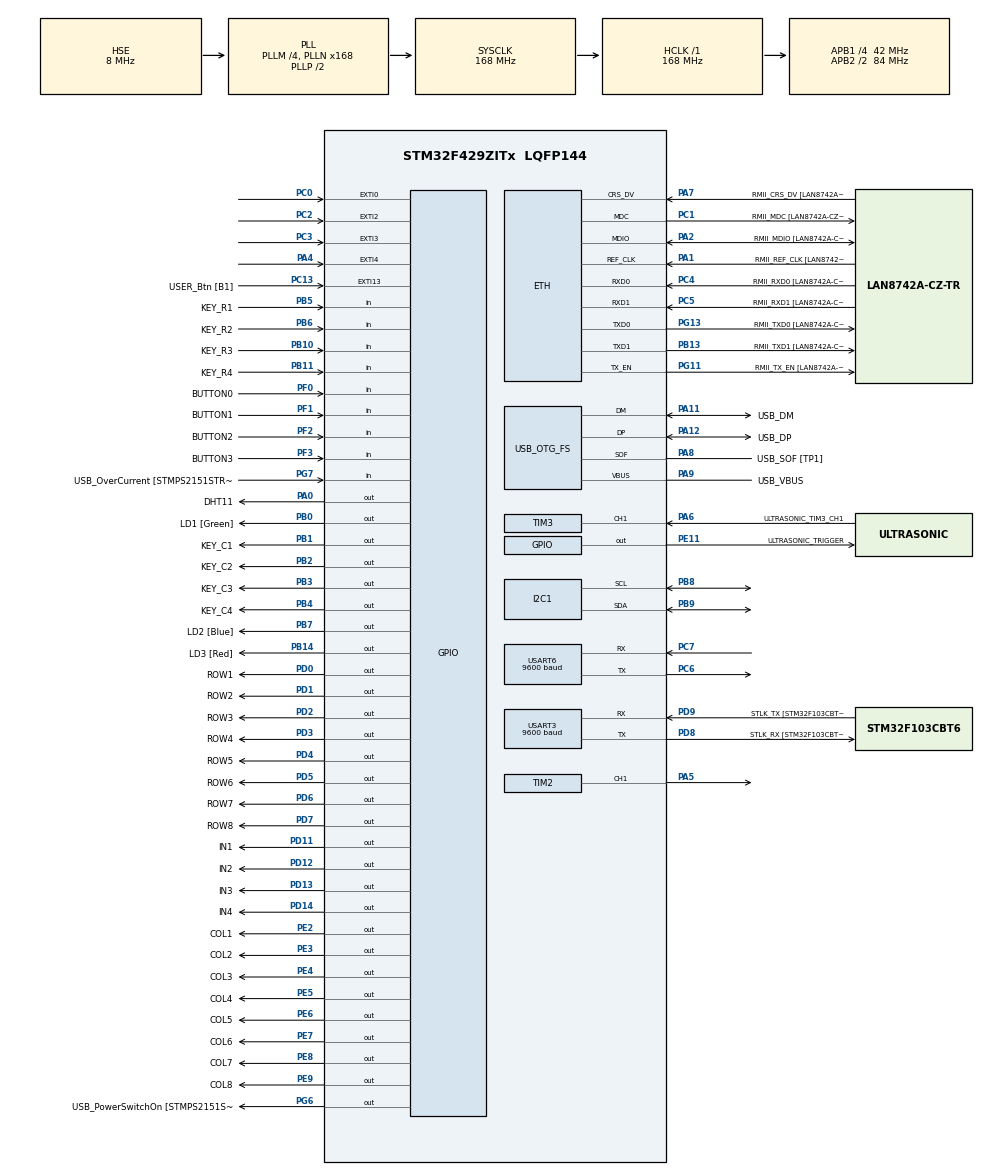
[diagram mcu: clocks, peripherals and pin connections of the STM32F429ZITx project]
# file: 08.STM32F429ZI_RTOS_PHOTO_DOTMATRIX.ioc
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ETH.MediaInterface=HAL_ETH_RMII_MODE
ETH.PHY_Name=LAN8742A_PHY_ADDRESS
ETH.PHY_Value=0
ETH.PhyAddress=0
FREERTOS.Mutexes01=myMutex01,Dynamic,NULL
FREERTOS.Tasks01=defaultTask,24,128,StartDefaultTask,Default,NULL,Dynamic,NULL,NULL;myTask02,8,128,StartTask02,Default,NULL,Dynamic,NULL,NULL;myTask03,8,128,StartTask03,Default,NULL,Dynamic,NULL,NULL;myTask04,8,128,StartTask04,Default,NULL,Dynamic,NULL,NULL
FREERTOS.configUSE_NEWLIB_REENTRANT=1
Mcu.Family=STM32F4
Mcu.Name=STM32F429ZITx
Mcu.Package=LQFP144
NVIC.EXTI0_IRQn=true\:5\:0\:false\:false\:true\:true\:true\:true\:true
NVIC.EXTI2_IRQn=true\:5\:0\:false\:false\:true\:true\:true\:true\:true
NVIC.EXTI3_IRQn=true\:5\:0\:false\:false\:true\:true\:true\:true\:true
NVIC.EXTI4_IRQn=true\:5\:0\:false\:false\:true\:true\:true\:true\:true
NVIC.I2C1_ER_IRQn=true\:5\:0\:false\:false\:true\:true\:true\:true\:true
NVIC.I2C1_EV_IRQn=true\:5\:0\:false\:false\:true\:true\:true\:true\:true
NVIC.PriorityGroup=NVIC_PRIORITYGROUP_4
NVIC.TIM1_TRG_COM_TIM11_IRQn=true\:5\:0\:false\:false\:true\:true\:true\:true\:true
NVIC.TIM1_UP_TIM10_IRQn=true\:15\:0\:false\:false\:true\:false\:true\:true\:true
NVIC.TIM2_IRQn=true\:5\:0\:false\:false\:true\:true\:true\:true\:true
NVIC.TIM3_IRQn=true\:5\:0\:false\:false\:true\:true\:true\:true\:true
NVIC.TimeBase=TIM1_UP_TIM10_IRQn
NVIC.TimeBaseIP=TIM1
NVIC.USART3_IRQn=true\:5\:0\:false\:false\:true\:true\:true\:true\:true
NVIC.USART6_IRQn=true\:5\:0\:false\:false\:true\:true\:true\:true\:true
PA0/WKUP.GPIO_Label=DHT11
PA0/WKUP.Signal=GPIO_Output
PA1.GPIO_Label=RMII_REF_CLK [LAN8742A-CZ-TR_REFCLK0]
PA1.Mode=RMII
PA1.Signal=ETH_REF_CLK
PA10.GPIO_Label=USB_ID
PA10.Signal=USB_OTG_FS_ID
PA11.GPIO_Label=USB_DM
PA11.Mode=Device_Only
PA11.Signal=USB_OTG_FS_DM
PA12.GPIO_Label=USB_DP
PA12.Mode=Device_Only
PA12.Signal=USB_OTG_FS_DP
PA13.GPIO_Label=TMS
PA13.Mode=Serial_Wire
PA13.Signal=SYS_JTMS-SWDIO
PA14.GPIO_Label=TCK
PA14.Mode=Serial_Wire
PA14.Signal=SYS_JTCK-SWCLK
PA2.GPIO_Label=RMII_MDIO [LAN8742A-CZ-TR_MDIO]
PA2.Mode=RMII
PA2.Signal=ETH_MDIO
PA4.GPIO_ModeDefaultEXTI=GPIO_MODE_IT_RISING
PA4.Signal=GPXTI4
PA5.Signal=S_TIM2_CH1_ETR
PA6.GPIO_Label=ULTRASONIC_TIM3_CH1
PA6.Signal=S_TIM3_CH1
PA7.GPIO_Label=RMII_CRS_DV [LAN8742A-CZ-TR_CRS_DV]
PA7.Mode=RMII
PA7.Signal=ETH_CRS_DV
PA8.GPIO_Label=USB_SOF [TP1]
PA8.Mode=Activate_SOF_FS
PA8.Signal=USB_OTG_FS_SOF
PA9.GPIO_Label=USB_VBUS
PA9.Mode=Activate_VBUS
PA9.Signal=USB_OTG_FS_VBUS
PB0.GPIO_Label=LD1 [Green]
PB0.Signal=GPIO_Output
PB1.GPIO_Label=KEY_C1
PB1.Signal=GPIO_Output
PB10.GPIO_Label=KEY_R3
PB10.GPIO_PuPd=GPIO_PULLUP
PB10.Signal=GPIO_Input
PB11.GPIO_Label=KEY_R4
PB11.GPIO_PuPd=GPIO_PULLUP
PB11.Signal=GPIO_Input
PB13.GPIO_Label=RMII_TXD1 [LAN8742A-CZ-TR_TXD1]
PB13.Mode=RMII
PB13.Signal=ETH_TXD1
PB14.GPIO_Label=LD3 [Red]
PB14.Signal=GPIO_Output
PB2/BOOT1.GPIO_Label=KEY_C2
PB2/BOOT1.Signal=GPIO_Output
PB3.GPIO_Label=KEY_C3
PB3.Signal=GPIO_Output
PB4.GPIO_Label=KEY_C4
PB4.Signal=GPIO_Output
PB5.GPIO_Label=KEY_R1
PB5.GPIO_PuPd=GPIO_PULLUP
PB5.Signal=GPIO_Input
PB6.GPIO_Label=KEY_R2
PB6.GPIO_PuPd=GPIO_PULLUP
PB6.Signal=GPIO_Input
PB7.GPIO_Label=LD2 [Blue]
PB7.Signal=GPIO_Output
PB8.Mode=I2C
PB8.Signal=I2C1_SCL
PB9.Mode=I2C
PB9.Signal=I2C1_SDA
PC0.Signal=GPXTI0
PC1.GPIO_Label=RMII_MDC [LAN8742A-CZ-TR_MDC]
PC1.Mode=RMII
PC1.Signal=ETH_MDC
PC13.GPIO_Label=USER_Btn [B1]
PC13.Signal=GPXTI13
PC14/OSC32_IN.Mode=LSE-External-Oscillator
PC14/OSC32_IN.Signal=RCC_OSC32_IN
PC15/OSC32_OUT.Mode=LSE-External-Oscillator
PC15/OSC32_OUT.Signal=RCC_OSC32_OUT
PC2.Signal=GPXTI2
PC3.Signal=GPXTI3
PC4.GPIO_Label=RMII_RXD0 [LAN8742A-CZ-TR_RXD0]
PC4.Mode=RMII
PC4.Signal=ETH_RXD0
PC5.GPIO_Label=RMII_RXD1 [LAN8742A-CZ-TR_RXD1]
PC5.Mode=RMII
PC5.Signal=ETH_RXD1
PC6.Mode=Asynchronous
PC6.Signal=USART6_TX
PC7.Mode=Asynchronous
PC7.Signal=USART6_RX
PD0.GPIO_Label=ROW1
PD0.Signal=GPIO_Output
PD1.GPIO_Label=ROW2
PD1.Signal=GPIO_Output
PD11.GPIO_Label=IN1
PD11.Signal=GPIO_Output
PD12.GPIO_Label=IN2
PD12.Signal=GPIO_Output
PD13.GPIO_Label=IN3
PD13.Signal=GPIO_Output
PD14.GPIO_Label=IN4
PD14.Signal=GPIO_Output
PD2.GPIO_Label=ROW3
PD2.Signal=GPIO_Output
PD3.GPIO_Label=ROW4
PD3.Signal=GPIO_Output
PD4.GPIO_Label=ROW5
PD4.Signal=GPIO_Output
PD5.GPIO_Label=ROW6
PD5.Signal=GPIO_Output
PD6.GPIO_Label=ROW7
PD6.Signal=GPIO_Output
PD7.GPIO_Label=ROW8
PD7.Signal=GPIO_Output
PD8.GPIO_Label=STLK_RX [STM32F103CBT6_PA3]
PD8.Mode=Asynchronous
PD8.Signal=USART3_TX
PD9.GPIO_Label=STLK_TX [STM32F103CBT6_PA2]
PD9.Mode=Asynchronous
PD9.Signal=USART3_RX
PE11.GPIO_Label=ULTRASONIC_TRIGGER
PE11.Signal=GPIO_Output
PE2.GPIO_Label=COL1
PE2.Signal=GPIO_Output
PE3.GPIO_Label=COL2
PE3.Signal=GPIO_Output
PE4.GPIO_Label=COL3
PE4.Signal=GPIO_Output
PE5.GPIO_Label=COL4
PE5.Signal=GPIO_Output
PE6.GPIO_Label=COL5
PE6.Signal=GPIO_Output
PE7.GPIO_Label=COL6
PE7.Signal=GPIO_Output
PE8.GPIO_Label=COL7
PE8.Signal=GPIO_Output
PE9.GPIO_Label=COL8
PE9.Signal=GPIO_Output
PF0.GPIO_Label=BUTTON0
PF0.Signal=GPIO_Input
PF1.GPIO_Label=BUTTON1
PF1.Signal=GPIO_Input
PF2.GPIO_Label=BUTTON2
PF2.Signal=GPIO_Input
PF3.GPIO_Label=BUTTON3
PF3.Signal=GPIO_Input
PG11.GPIO_Label=RMII_TX_EN [LAN8742A-CZ-TR_TXEN]
PG11.Mode=RMII
PG11.Signal=ETH_TX_EN
PG13.GPIO_Label=RMII_TXD0 [LAN8742A-CZ-TR_TXD0]
PG13.Mode=RMII
PG13.Signal=ETH_TXD0
PG6.GPIO_Label=USB_PowerSwitchOn [STMPS2151STR_EN]
PG6.Signal=GPIO_Output
PG7.GPIO_Label=USB_OverCurrent [STMPS2151STR_FAULT]
PG7.Signal=GPIO_Input
PH0/OSC_IN.GPIO_Label=MCO [STM32F103CBT6_PA8]
PH0/OSC_IN.Mode=HSE-External-Clock-Source
PH0/OSC_IN.Signal=RCC_OSC_IN
PH1/OSC_OUT.Mode=HSE-External-Clock-Source
PH1/OSC_OUT.Signal=RCC_OSC_OUT
ProjectManager.HeapSize=0x200
ProjectManager.StackSize=0x400
ProjectManager.TargetToolchain=STM32CubeIDE
RCC.48MHZClocksFreq_Value=48000000
RCC.AHBFreq_Value=168000000
RCC.APB1CLKDivider=RCC_HCLK_DIV4
RCC.APB1Freq_Value=42000000
RCC.APB1TimFreq_Value=84000000
RCC.APB2CLKDivider=RCC_HCLK_DIV2
RCC.APB2Freq_Value=84000000
RCC.APB2TimFreq_Value=168000000
RCC.CortexFreq_Value=168000000
RCC.HCLKFreq_Value=168000000
RCC.HSE_VALUE=8000000
RCC.HSI_VALUE=16000000
RCC.PLLM=4
RCC.PLLMUL=RCC_PLL_MUL9
RCC.PLLN=168
RCC.PLLQ=7
RCC.PRESCALERUSB=RCC_USBCLKSOURCE_PLL_DIV1_5
RCC.SYSCLKFreq_VALUE=168000000
RCC.SYSCLKSource=RCC_SYSCLKSOURCE_PLLCLK
RCC.SYSCLKSourceVirtual=RCC_SYSCLKSOURCE_PLLCLK
RCC.USBFreq_Value=48000000
RCC.VCOOutputFreq_Value=336000000
RTC.Date=5
RTC.Hours=13
RTC.Minutes=37
RTC.Month=RTC_MONTH_JULY
RTC.WeekDay=RTC_WEEKDAY_WEDNESDAY
RTC.Year=23
SH.S_TIM2_CH1_ETR.0=TIM2_CH1,PWM Generation1 CH1
SH.S_TIM3_CH1.0=TIM3_CH1,Input_Capture1_from_TI1
TIM10.Period=10000-1
TIM10.Prescaler=168-1
TIM11.Prescaler=168-1
TIM2.Channel-PWM\ Generation1\ CH1=TIM_CHANNEL_1
TIM2.Period=1000-1
TIM2.Prescaler=3360-1
TIM2.Pulse-PWM\ Generation1\ CH1=500-1
TIM3.Channel-Input_Capture1_from_TI1=TIM_CHANNEL_1
TIM3.ICPolarity_CH1=TIM_INPUTCHANNELPOLARITY_BOTHEDGE
TIM3.Prescaler=168-1
USART3.BaudRate=9600
USART3.VirtualMode=VM_ASYNC
USART6.BaudRate=9600
USART6.VirtualMode=VM_ASYNC
USB_OTG_FS.VirtualMode=Device_Only
VP_FREERTOS_VS_CMSIS_V2.Mode=CMSIS_V2
VP_RTC_VS_RTC_Activate.Mode=RTC_Enabled
VP_RTC_VS_RTC_Calendar.Mode=RTC_Calendar
VP_SYS_VS_tim1.Mode=TIM1
VP_TIM10_VS_ClockSourceINT.Mode=Enable_Timer
VP_TIM11_VS_ClockSourceINT.Mode=Enable_Timer
VP_TIM3_VS_ClockSourceINT.Mode=Internal
board=NUCLEO-F429ZI

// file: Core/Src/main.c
/* USER CODE BEGIN Header */
/**
  ******************************************************************************
  * @file           : main.c
  * @brief          : Main program body
  ******************************************************************************
  * @attention
  *
  * Copyright (c) 2023 STMicroelectronics.
  * All rights reserved.
  *
  * This software is licensed under terms that can be found in the LICENSE file
  * in the root directory of this software component.
  * If no LICENSE file comes with this software, it is provided AS-IS.
  *
  ******************************************************************************
  */
/* USER CODE END Header */
#include "main.h"
#include "string.h"
#include "cmsis_os.h"

ETH_TxPacketConfig TxConfig;
ETH_DMADescTypeDef  DMARxDscrTab[ETH_RX_DESC_CNT]; /* Ethernet Rx DMA Descriptors */
ETH_DMADescTypeDef  DMATxDscrTab[ETH_TX_DESC_CNT]; /* Ethernet Tx DMA Descriptors */

ETH_HandleTypeDef heth;

I2C_HandleTypeDef hi2c1;

RTC_HandleTypeDef hrtc;

TIM_HandleTypeDef htim2;
TIM_HandleTypeDef htim3;
TIM_HandleTypeDef htim10;
TIM_HandleTypeDef htim11;

UART_HandleTypeDef huart3;
UART_HandleTypeDef huart6;

PCD_HandleTypeDef hpcd_USB_OTG_FS;

/* Definitions for defaultTask */
osThreadId_t defaultTaskHandle;
const osThreadAttr_t defaultTask_attributes = {
  .name = "defaultTask",
  .stack_size = 128 * 4,
  .priority = (osPriority_t) osPriorityNormal,
};
/* Definitions for myTask02 */
osThreadId_t myTask02Handle;
const osThreadAttr_t myTask02_attributes = {
  .name = "myTask02",
  .stack_size = 128 * 4,
  .priority = (osPriority_t) osPriorityLow,
};
/* Definitions for myTask03 */
osThreadId_t myTask03Handle;
const osThreadAttr_t myTask03_attributes = {
  .name = "myTask03",
  .stack_size = 128 * 4,
  .priority = (osPriority_t) osPriorityLow,
};
/* Definitions for myTask04 */
osThreadId_t myTask04Handle;
const osThreadAttr_t myTask04_attributes = {
  .name = "myTask04",
  .stack_size = 128 * 4,
  .priority = (osPriority_t) osPriorityLow,
};
/* Definitions for myMutex01 */
osMutexId_t myMutex01Handle;
const osMutexAttr_t myMutex01_attributes = {
  .name = "myMutex01"
};
/* USER CODE BEGIN PV */
uint8_t rx_data; // PC data #define uint8_t unsigned char
uint8_t bt_data; // BT data
/* USER CODE END PV */

void SystemClock_Config(void);
static void MX_GPIO_Init(void);
static void MX_ETH_Init(void);
static void MX_USART3_UART_Init(void);
static void MX_USB_OTG_FS_PCD_Init(void);
static void MX_TIM10_Init(void);
static void MX_TIM11_Init(void);
static void MX_RTC_Init(void);
static void MX_I2C1_Init(void);
static void MX_USART6_UART_Init(void);
static void MX_TIM2_Init(void);
static void MX_TIM3_Init(void);
void StartDefaultTask(void *argument);
void StartTask02(void *argument);
void StartTask03(void *argument);
void StartTask04(void *argument);

/* USER CODE BEGIN PFP */
extern void pc_command_processing(void);
extern void bt_command_processing(void);
extern void get_rtc_time(void);
extern void i2c_lcd_main(void);
extern void i2c_lcd_init(void);
extern void DHT11_main(void);
extern void DHT11_Init(void);
extern void DHT11_processing(void);
extern void button0_status_check(void);
extern void calculator(void);
extern void stepmotor_main_test();
extern void servo_motor_test_main();
extern void ultrasonic_main(void);
extern void stepmotor_main();
//extern int dotmatrix_main_test(void);
extern int dotmatrix_main(void);
extern void init_dotmatrix(void);
extern void stepmotor_elva(void);
extern void elevator_default(void);

extern int led1toggle_time;   // uart3.c
extern int led2toggle_time;
extern int led3toggle_time;
extern int stepmotor_status;
extern int floor_status;

void delay_us(unsigned long us);

int func_num = 0;
void (*fp[])()=
{
	pc_command_processing, 	//0
	bt_command_processing, 	//1
	get_rtc_time,			//2
	DHT11_processing,		//3
	button0_status_check,	//4
	calculator				//5
};
/* USER CODE END PFP */

/* USER CODE BEGIN 0 */
//----------  printf start ----------
#ifdef __GNUC__
/* With GCC, small printf (option LD Linker->Libraries->Small printf
   set to 'Yes') calls __io_putchar() */
#define PUTCHAR_PROTOTYPE int __io_putchar(int ch)
#else
#define PUTCHAR_PROTOTYPE int fputc(int ch, FILE *f)
#endif /* __GNUC_ */
/**
  * @brief  Retargets the C library printf function to the USART.
  * @param  None
  * @retval None
  */
PUTCHAR_PROTOTYPE   // Add for printf
{
  /* Place your implementation of fputc here */
  /* e.g. write a character to the USART3 and Loop until the end of transmission */
  HAL_UART_Transmit(&huart3, (uint8_t *)&ch, 1, 0xFFFF); // uart2 <- 1 char ride

  return ch;
}
//----------  printf end ----------
volatile int t1ms_counter = 0;
volatile int TIM11_1ms_counter = 0;
volatile int t10ms_ultrasonic;	//trigger timer
void HAL_SYSTICK_CallBack(void)
{
	t1ms_counter++;
	TIM11_1ms_counter++;
}
//1. move from Driver/STM32F4xx_HAL_Driver/Src/stm32f4xx_hal_gpio.c to here
//2. enter here every External Interrupt
volatile int ext_int_no = -1;	//GPIO_0?�� ?���????? ?��문에 초기 값으�????? -1?�� setting
#define IDLE 0
#define FIRST 1
#define SECOND 2
#define THIRD 3
#define FOURTH 4
void HAL_GPIO_EXTI_Callback(uint16_t GPIO_Pin)
{
	switch(GPIO_Pin)
	{
	case GPIO_PIN_0 :	//EXT INT 0
		ext_int_no = GPIO_PIN_0;
		nucleo_stm32f429zi_led_off();
		HAL_GPIO_WritePin(GPIOB, GPIO_PIN_0, 1);
		floor_status = FIRST;
printf("1\n");
//		stepmotor_status = IDLE;
		break;
	case GPIO_PIN_2 :	//EXT INT 2
		ext_int_no = GPIO_PIN_2;
		nucleo_stm32f429zi_led_off();
		HAL_GPIO_WritePin(GPIOB, GPIO_PIN_7, 1);
		floor_status = SECOND;
printf("2\n");
//		stepmotor_status = IDLE;
		break;
	case GPIO_PIN_3 :	//EXT INT 3
		ext_int_no = GPIO_PIN_3;
		nucleo_stm32f429zi_led_off();
		HAL_GPIO_WritePin(GPIOB, GPIO_PIN_14, 1);
		floor_status = THIRD;
printf("3\n");
		break;
	case GPIO_PIN_4 :	//EXT INT 4
		ext_int_no = GPIO_PIN_4;
		nucleo_stm32f429zi_led_off();
		HAL_GPIO_WritePin(GPIOB, GPIO_PIN_0, 1);
		HAL_GPIO_WritePin(GPIOB, GPIO_PIN_7, 1);
		HAL_GPIO_WritePin(GPIOB, GPIO_PIN_14, 1);
		floor_status = FOURTH;
printf("4\n");
		break;
	}
}

volatile int TIM10_10ms_counter = 0;
volatile int TIM10_10ms_keypad_scan_timer = 0;
extern int keypad_scanning();

//
//	delay_us(10);
void delay_us(unsigned long us)
{
	// TCNT = 0; ex) AVR
	__HAL_TIM_SET_COUNTER(&htim11,0);  // clear timer counter
	while(__HAL_TIM_GET_COUNTER(&htim11) < us)  // wait counter value until reach
	{
		;
	}
}

// led off on STM32F429ZI
void nucleo_stm32f429zi_led_off()
{
	 HAL_GPIO_WritePin(GPIOB, GPIO_PIN_0, 0);
	 HAL_GPIO_WritePin(GPIOB, GPIO_PIN_7, 0);
	 HAL_GPIO_WritePin(GPIOB, GPIO_PIN_14, 0);
}
/* USER CODE END 0 */

int main(void)
{

  /* MCU Configuration--------------------------------------------------------*/

  /* Reset of all peripherals, Initializes the Flash interface and the Systick. */
  HAL_Init();

  /* Configure the system clock */
  SystemClock_Config();

  /* Initialize all configured peripherals */
  MX_GPIO_Init();
  MX_ETH_Init();
  MX_USART3_UART_Init();
  MX_USB_OTG_FS_PCD_Init();
  MX_TIM10_Init();
  MX_TIM11_Init();
  MX_RTC_Init();
  MX_I2C1_Init();
  MX_USART6_UART_Init();
  MX_TIM2_Init();
  MX_TIM3_Init();
  /* USER CODE BEGIN 2 */
  i2c_lcd_init();  // initialize LCD
  DHT11_Init();
  init_dotmatrix();
  HAL_TIM_Base_Start_IT(&htim10); // ADD_MINGYU_230704
  HAL_TIM_Base_Start_IT(&htim11);
  HAL_UART_Receive_IT(&huart3, &rx_data, 1); // PC assign to RX INTerrupt
  HAL_UART_Receive_IT(&huart6, &bt_data, 1); // BT assign to RX INTerrupt
  HAL_GPIO_WritePin(GPIOB, GPIO_PIN_0, 0);
  HAL_GPIO_WritePin(GPIOB, GPIO_PIN_7, 0);
  HAL_GPIO_WritePin(GPIOB, GPIO_PIN_14, 0);
  HAL_TIM_PWM_Start(&htim2, TIM_CHANNEL_1);	//add SERVO_MOTOR_PWM
  HAL_TIM_IC_Start_IT(&htim3, TIM_CHANNEL_1);	//for count pulse(both rising edge & falling edge)
//  DHT11_main();

//  i2c_lcd_main();
//  stepmotor_main_test();
//  servo_motor_test_main();
//  ultrasonic_main();
//printf("elevator_default/n");
//  dotmatrix_main_test();
//	elevator_default();

  /* USER CODE END 2 */

  /* Init scheduler */
  osKernelInitialize();
  /* Create the mutex(es) */
  /* creation of myMutex01 */
  myMutex01Handle = osMutexNew(&myMutex01_attributes);

  /* Create the thread(s) */
  /* creation of defaultTask */
  defaultTaskHandle = osThreadNew(StartDefaultTask, NULL, &defaultTask_attributes);

  /* creation of myTask02 */
  myTask02Handle = osThreadNew(StartTask02, NULL, &myTask02_attributes);

  /* creation of myTask03 */
  myTask03Handle = osThreadNew(StartTask03, NULL, &myTask03_attributes);

  /* creation of myTask04 */
  myTask04Handle = osThreadNew(StartTask04, NULL, &myTask04_attributes);

  /* Start scheduler */
  osKernelStart();
  /* We should never get here as control is now taken by the scheduler */
  /* Infinite loop */
  /* USER CODE BEGIN WHILE */
  while (1)
  {
	  ;
#if 1
//	fp[func_num]();

#else	//original
	  pc_command_processing();
	  bt_command_processing();
	  // YYYY-MM-DD HH:MM:SS
	  get_rtc_time();
	  DHT11_processing();
	  button0_status_check();
	  calculator();

	  if (led1toggle_time && TIM10_10ms_counter >= led1toggle_time)  // led1toggle_time
		  {                                                          // led1toggle_time > 0
			  TIM10_10ms_counter = 0;
			  HAL_GPIO_TogglePin(GPIOB, GPIO_PIN_0);
		  }
	  if (led2toggle_time && t1ms_counter >= led2toggle_time)
		  {
			  t1ms_counter = 0;
			  HAL_GPIO_TogglePin(GPIOB, GPIO_PIN_7);
		  }
	  if (led3toggle_time && TIM11_1ms_counter >= led3toggle_time)
		  {
			  TIM11_1ms_counter = 0;
			  HAL_GPIO_TogglePin(GPIOB, GPIO_PIN_14);
		  }
    /* USER CODE END WHILE */

    /* USER CODE BEGIN 3 */
#endif
  }

  /* USER CODE END 3 */
}

void SystemClock_Config(void)
{
  RCC_OscInitTypeDef RCC_OscInitStruct = {0};
  RCC_ClkInitTypeDef RCC_ClkInitStruct = {0};

  /** Configure the main internal regulator output voltage
  */
  __HAL_RCC_PWR_CLK_ENABLE();
  __HAL_PWR_VOLTAGESCALING_CONFIG(PWR_REGULATOR_VOLTAGE_SCALE1);

  /** Initializes the RCC Oscillators according to the specified parameters
  * in the RCC_OscInitTypeDef structure.
  */
  RCC_OscInitStruct.OscillatorType = RCC_OSCILLATORTYPE_LSI|RCC_OSCILLATORTYPE_HSE;
  RCC_OscInitStruct.HSEState = RCC_HSE_BYPASS;
  RCC_OscInitStruct.LSIState = RCC_LSI_ON;
  RCC_OscInitStruct.PLL.PLLState = RCC_PLL_ON;
  RCC_OscInitStruct.PLL.PLLSource = RCC_PLLSOURCE_HSE;
  RCC_OscInitStruct.PLL.PLLM = 4;
  RCC_OscInitStruct.PLL.PLLN = 168;
  RCC_OscInitStruct.PLL.PLLP = RCC_PLLP_DIV2;
  RCC_OscInitStruct.PLL.PLLQ = 7;
  if (HAL_RCC_OscConfig(&RCC_OscInitStruct) != HAL_OK)
  {
    Error_Handler();
  }

  /** Initializes the CPU, AHB and APB buses clocks
  */
  RCC_ClkInitStruct.ClockType = RCC_CLOCKTYPE_HCLK|RCC_CLOCKTYPE_SYSCLK
                              |RCC_CLOCKTYPE_PCLK1|RCC_CLOCKTYPE_PCLK2;
  RCC_ClkInitStruct.SYSCLKSource = RCC_SYSCLKSOURCE_PLLCLK;
  RCC_ClkInitStruct.AHBCLKDivider = RCC_SYSCLK_DIV1;
  RCC_ClkInitStruct.APB1CLKDivider = RCC_HCLK_DIV4;
  RCC_ClkInitStruct.APB2CLKDivider = RCC_HCLK_DIV2;

  if (HAL_RCC_ClockConfig(&RCC_ClkInitStruct, FLASH_LATENCY_5) != HAL_OK)
  {
    Error_Handler();
  }
}

static void MX_ETH_Init(void)
{

   static uint8_t MACAddr[6];

  heth.Instance = ETH;
  MACAddr[0] = 0x00;
  MACAddr[1] = 0x80;
  MACAddr[2] = 0xE1;
  MACAddr[3] = 0x00;
  MACAddr[4] = 0x00;
  MACAddr[5] = 0x00;
  heth.Init.MACAddr = &MACAddr[0];
  heth.Init.MediaInterface = HAL_ETH_RMII_MODE;
  heth.Init.TxDesc = DMATxDscrTab;
  heth.Init.RxDesc = DMARxDscrTab;
  heth.Init.RxBuffLen = 1524;

  if (HAL_ETH_Init(&heth) != HAL_OK)
  {
    Error_Handler();
  }

  memset(&TxConfig, 0 , sizeof(ETH_TxPacketConfig));
  TxConfig.Attributes = ETH_TX_PACKETS_FEATURES_CSUM | ETH_TX_PACKETS_FEATURES_CRCPAD;
  TxConfig.ChecksumCtrl = ETH_CHECKSUM_IPHDR_PAYLOAD_INSERT_PHDR_CALC;
  TxConfig.CRCPadCtrl = ETH_CRC_PAD_INSERT;

}

static void MX_I2C1_Init(void)
{

  hi2c1.Instance = I2C1;
  hi2c1.Init.ClockSpeed = 100000;
  hi2c1.Init.DutyCycle = I2C_DUTYCYCLE_2;
  hi2c1.Init.OwnAddress1 = 0;
  hi2c1.Init.AddressingMode = I2C_ADDRESSINGMODE_7BIT;
  hi2c1.Init.DualAddressMode = I2C_DUALADDRESS_DISABLE;
  hi2c1.Init.OwnAddress2 = 0;
  hi2c1.Init.GeneralCallMode = I2C_GENERALCALL_DISABLE;
  hi2c1.Init.NoStretchMode = I2C_NOSTRETCH_DISABLE;
  if (HAL_I2C_Init(&hi2c1) != HAL_OK)
  {
    Error_Handler();
  }

  /** Configure Analogue filter
  */
  if (HAL_I2CEx_ConfigAnalogFilter(&hi2c1, I2C_ANALOGFILTER_ENABLE) != HAL_OK)
  {
    Error_Handler();
  }

  /** Configure Digital filter
  */
  if (HAL_I2CEx_ConfigDigitalFilter(&hi2c1, 0) != HAL_OK)
  {
    Error_Handler();
  }

}

static void MX_RTC_Init(void)
{

  RTC_TimeTypeDef sTime = {0};
  RTC_DateTypeDef sDate = {0};

  /** Initialize RTC Only
  */
  hrtc.Instance = RTC;
  hrtc.Init.HourFormat = RTC_HOURFORMAT_24;
  hrtc.Init.AsynchPrediv = 127;
  hrtc.Init.SynchPrediv = 255;
  hrtc.Init.OutPut = RTC_OUTPUT_DISABLE;
  hrtc.Init.OutPutPolarity = RTC_OUTPUT_POLARITY_HIGH;
  hrtc.Init.OutPutType = RTC_OUTPUT_TYPE_OPENDRAIN;
  if (HAL_RTC_Init(&hrtc) != HAL_OK)
  {
    Error_Handler();
  }

  /** Initialize RTC and set the Time and Date
  */
  sTime.Hours = 0x13;
  sTime.Minutes = 0x37;
  sTime.Seconds = 0x0;
  sTime.DayLightSaving = RTC_DAYLIGHTSAVING_NONE;
  sTime.StoreOperation = RTC_STOREOPERATION_RESET;
  if (HAL_RTC_SetTime(&hrtc, &sTime, RTC_FORMAT_BCD) != HAL_OK)
  {
    Error_Handler();
  }
  sDate.WeekDay = RTC_WEEKDAY_WEDNESDAY;
  sDate.Month = RTC_MONTH_JULY;
  sDate.Date = 0x5;
  sDate.Year = 0x23;

  if (HAL_RTC_SetDate(&hrtc, &sDate, RTC_FORMAT_BCD) != HAL_OK)
  {
    Error_Handler();
  }

}

static void MX_TIM2_Init(void)
{

  TIM_MasterConfigTypeDef sMasterConfig = {0};
  TIM_OC_InitTypeDef sConfigOC = {0};

  htim2.Instance = TIM2;
  htim2.Init.Prescaler = 3360-1;
  htim2.Init.CounterMode = TIM_COUNTERMODE_UP;
  htim2.Init.Period = 1000-1;
  htim2.Init.ClockDivision = TIM_CLOCKDIVISION_DIV1;
  htim2.Init.AutoReloadPreload = TIM_AUTORELOAD_PRELOAD_DISABLE;
  if (HAL_TIM_PWM_Init(&htim2) != HAL_OK)
  {
    Error_Handler();
  }
  sMasterConfig.MasterOutputTrigger = TIM_TRGO_RESET;
  sMasterConfig.MasterSlaveMode = TIM_MASTERSLAVEMODE_DISABLE;
  if (HAL_TIMEx_MasterConfigSynchronization(&htim2, &sMasterConfig) != HAL_OK)
  {
    Error_Handler();
  }
  sConfigOC.OCMode = TIM_OCMODE_PWM1;
  sConfigOC.Pulse = 500-1;
  sConfigOC.OCPolarity = TIM_OCPOLARITY_HIGH;
  sConfigOC.OCFastMode = TIM_OCFAST_DISABLE;
  if (HAL_TIM_PWM_ConfigChannel(&htim2, &sConfigOC, TIM_CHANNEL_1) != HAL_OK)
  {
    Error_Handler();
  }
  HAL_TIM_MspPostInit(&htim2);

}

static void MX_TIM3_Init(void)
{

  TIM_ClockConfigTypeDef sClockSourceConfig = {0};
  TIM_MasterConfigTypeDef sMasterConfig = {0};
  TIM_IC_InitTypeDef sConfigIC = {0};

  htim3.Instance = TIM3;
  htim3.Init.Prescaler = 168-1;
  htim3.Init.CounterMode = TIM_COUNTERMODE_UP;
  htim3.Init.Period = 65535;
  htim3.Init.ClockDivision = TIM_CLOCKDIVISION_DIV1;
  htim3.Init.AutoReloadPreload = TIM_AUTORELOAD_PRELOAD_DISABLE;
  if (HAL_TIM_Base_Init(&htim3) != HAL_OK)
  {
    Error_Handler();
  }
  sClockSourceConfig.ClockSource = TIM_CLOCKSOURCE_INTERNAL;
  if (HAL_TIM_ConfigClockSource(&htim3, &sClockSourceConfig) != HAL_OK)
  {
    Error_Handler();
  }
  if (HAL_TIM_IC_Init(&htim3) != HAL_OK)
  {
    Error_Handler();
  }
  sMasterConfig.MasterOutputTrigger = TIM_TRGO_RESET;
  sMasterConfig.MasterSlaveMode = TIM_MASTERSLAVEMODE_DISABLE;
  if (HAL_TIMEx_MasterConfigSynchronization(&htim3, &sMasterConfig) != HAL_OK)
  {
    Error_Handler();
  }
  sConfigIC.ICPolarity = TIM_INPUTCHANNELPOLARITY_BOTHEDGE;
  sConfigIC.ICSelection = TIM_ICSELECTION_DIRECTTI;
  sConfigIC.ICPrescaler = TIM_ICPSC_DIV1;
  sConfigIC.ICFilter = 0;
  if (HAL_TIM_IC_ConfigChannel(&htim3, &sConfigIC, TIM_CHANNEL_1) != HAL_OK)
  {
    Error_Handler();
  }

}

static void MX_TIM10_Init(void)
{

  htim10.Instance = TIM10;
  htim10.Init.Prescaler = 168-1;
  htim10.Init.CounterMode = TIM_COUNTERMODE_UP;
  htim10.Init.Period = 10000-1;
  htim10.Init.ClockDivision = TIM_CLOCKDIVISION_DIV1;
  htim10.Init.AutoReloadPreload = TIM_AUTORELOAD_PRELOAD_DISABLE;
  if (HAL_TIM_Base_Init(&htim10) != HAL_OK)
  {
    Error_Handler();
  }

}

static void MX_TIM11_Init(void)
{

  htim11.Instance = TIM11;
  htim11.Init.Prescaler = 168-1;
  htim11.Init.CounterMode = TIM_COUNTERMODE_UP;
  htim11.Init.Period = 65535;
  htim11.Init.ClockDivision = TIM_CLOCKDIVISION_DIV1;
  htim11.Init.AutoReloadPreload = TIM_AUTORELOAD_PRELOAD_DISABLE;
  if (HAL_TIM_Base_Init(&htim11) != HAL_OK)
  {
    Error_Handler();
  }

}

static void MX_USART3_UART_Init(void)
{

  huart3.Instance = USART3;
  huart3.Init.BaudRate = 9600;
  huart3.Init.WordLength = UART_WORDLENGTH_8B;
  huart3.Init.StopBits = UART_STOPBITS_1;
  huart3.Init.Parity = UART_PARITY_NONE;
  huart3.Init.Mode = UART_MODE_TX_RX;
  huart3.Init.HwFlowCtl = UART_HWCONTROL_NONE;
  huart3.Init.OverSampling = UART_OVERSAMPLING_16;
  if (HAL_UART_Init(&huart3) != HAL_OK)
  {
    Error_Handler();
  }

}

static void MX_USART6_UART_Init(void)
{

  huart6.Instance = USART6;
  huart6.Init.BaudRate = 9600;
  huart6.Init.WordLength = UART_WORDLENGTH_8B;
  huart6.Init.StopBits = UART_STOPBITS_1;
  huart6.Init.Parity = UART_PARITY_NONE;
  huart6.Init.Mode = UART_MODE_TX_RX;
  huart6.Init.HwFlowCtl = UART_HWCONTROL_NONE;
  huart6.Init.OverSampling = UART_OVERSAMPLING_16;
  if (HAL_UART_Init(&huart6) != HAL_OK)
  {
    Error_Handler();
  }

}

static void MX_USB_OTG_FS_PCD_Init(void)
{

  hpcd_USB_OTG_FS.Instance = USB_OTG_FS;
  hpcd_USB_OTG_FS.Init.dev_endpoints = 4;
  hpcd_USB_OTG_FS.Init.speed = PCD_SPEED_FULL;
  hpcd_USB_OTG_FS.Init.dma_enable = DISABLE;
  hpcd_USB_OTG_FS.Init.phy_itface = PCD_PHY_EMBEDDED;
  hpcd_USB_OTG_FS.Init.Sof_enable = ENABLE;
  hpcd_USB_OTG_FS.Init.low_power_enable = DISABLE;
  hpcd_USB_OTG_FS.Init.lpm_enable = DISABLE;
  hpcd_USB_OTG_FS.Init.vbus_sensing_enable = ENABLE;
  hpcd_USB_OTG_FS.Init.use_dedicated_ep1 = DISABLE;
  if (HAL_PCD_Init(&hpcd_USB_OTG_FS) != HAL_OK)
  {
    Error_Handler();
  }

}

static void MX_GPIO_Init(void)
{
  GPIO_InitTypeDef GPIO_InitStruct = {0};

  /* GPIO Ports Clock Enable */
  __HAL_RCC_GPIOE_CLK_ENABLE();
  __HAL_RCC_GPIOC_CLK_ENABLE();
  __HAL_RCC_GPIOF_CLK_ENABLE();
  __HAL_RCC_GPIOH_CLK_ENABLE();
  __HAL_RCC_GPIOA_CLK_ENABLE();
  __HAL_RCC_GPIOB_CLK_ENABLE();
  __HAL_RCC_GPIOD_CLK_ENABLE();
  __HAL_RCC_GPIOG_CLK_ENABLE();

  /*Configure GPIO pin Output Level */
  HAL_GPIO_WritePin(GPIOE, COL1_Pin|COL2_Pin|COL3_Pin|COL4_Pin
                          |COL5_Pin|COL6_Pin|COL7_Pin|COL8_Pin
                          |ULTRASONIC_TRIGGER_Pin, GPIO_PIN_RESET);

  /*Configure GPIO pin Output Level */
  HAL_GPIO_WritePin(DHT11_GPIO_Port, DHT11_Pin, GPIO_PIN_RESET);

  /*Configure GPIO pin Output Level */
  HAL_GPIO_WritePin(GPIOB, LD1_Pin|KEY_C1_Pin|KEY_C2_Pin|LD3_Pin
                          |KEY_C3_Pin|KEY_C4_Pin|LD2_Pin, GPIO_PIN_RESET);

  /*Configure GPIO pin Output Level */
  HAL_GPIO_WritePin(GPIOD, IN1_Pin|IN2_Pin|IN3_Pin|IN4_Pin
                          |ROW1_Pin|ROW2_Pin|ROW3_Pin|ROW4_Pin
                          |ROW5_Pin|ROW6_Pin|ROW7_Pin|ROW8_Pin, GPIO_PIN_RESET);

  /*Configure GPIO pin Output Level */
  HAL_GPIO_WritePin(USB_PowerSwitchOn_GPIO_Port, USB_PowerSwitchOn_Pin, GPIO_PIN_RESET);

  /*Configure GPIO pins : COL1_Pin COL2_Pin COL3_Pin COL4_Pin
                           COL5_Pin COL6_Pin COL7_Pin COL8_Pin
                           ULTRASONIC_TRIGGER_Pin */
  GPIO_InitStruct.Pin = COL1_Pin|COL2_Pin|COL3_Pin|COL4_Pin
                          |COL5_Pin|COL6_Pin|COL7_Pin|COL8_Pin
                          |ULTRASONIC_TRIGGER_Pin;
  GPIO_InitStruct.Mode = GPIO_MODE_OUTPUT_PP;
  GPIO_InitStruct.Pull = GPIO_NOPULL;
  GPIO_InitStruct.Speed = GPIO_SPEED_FREQ_LOW;
  HAL_GPIO_Init(GPIOE, &GPIO_InitStruct);

  /*Configure GPIO pins : USER_Btn_Pin PC0 PC2 PC3 */
  GPIO_InitStruct.Pin = USER_Btn_Pin|GPIO_PIN_0|GPIO_PIN_2|GPIO_PIN_3;
  GPIO_InitStruct.Mode = GPIO_MODE_IT_RISING;
  GPIO_InitStruct.Pull = GPIO_NOPULL;
  HAL_GPIO_Init(GPIOC, &GPIO_InitStruct);

  /*Configure GPIO pins : BUTTON0_Pin BUTTON1_Pin BUTTON2_Pin BUTTON3_Pin */
  GPIO_InitStruct.Pin = BUTTON0_Pin|BUTTON1_Pin|BUTTON2_Pin|BUTTON3_Pin;
  GPIO_InitStruct.Mode = GPIO_MODE_INPUT;
  GPIO_InitStruct.Pull = GPIO_NOPULL;
  HAL_GPIO_Init(GPIOF, &GPIO_InitStruct);

  /*Configure GPIO pin : DHT11_Pin */
  GPIO_InitStruct.Pin = DHT11_Pin;
  GPIO_InitStruct.Mode = GPIO_MODE_OUTPUT_PP;
  GPIO_InitStruct.Pull = GPIO_NOPULL;
  GPIO_InitStruct.Speed = GPIO_SPEED_FREQ_LOW;
  HAL_GPIO_Init(DHT11_GPIO_Port, &GPIO_InitStruct);

  /*Configure GPIO pin : PA4 */
  GPIO_InitStruct.Pin = GPIO_PIN_4;
  GPIO_InitStruct.Mode = GPIO_MODE_IT_RISING;
  GPIO_InitStruct.Pull = GPIO_NOPULL;
  HAL_GPIO_Init(GPIOA, &GPIO_InitStruct);

  /*Configure GPIO pins : LD1_Pin KEY_C1_Pin KEY_C2_Pin LD3_Pin
                           KEY_C3_Pin KEY_C4_Pin LD2_Pin */
  GPIO_InitStruct.Pin = LD1_Pin|KEY_C1_Pin|KEY_C2_Pin|LD3_Pin
                          |KEY_C3_Pin|KEY_C4_Pin|LD2_Pin;
  GPIO_InitStruct.Mode = GPIO_MODE_OUTPUT_PP;
  GPIO_InitStruct.Pull = GPIO_NOPULL;
  GPIO_InitStruct.Speed = GPIO_SPEED_FREQ_LOW;
  HAL_GPIO_Init(GPIOB, &GPIO_InitStruct);

  /*Configure GPIO pins : KEY_R3_Pin KEY_R4_Pin KEY_R1_Pin KEY_R2_Pin */
  GPIO_InitStruct.Pin = KEY_R3_Pin|KEY_R4_Pin|KEY_R1_Pin|KEY_R2_Pin;
  GPIO_InitStruct.Mode = GPIO_MODE_INPUT;
  GPIO_InitStruct.Pull = GPIO_PULLUP;
  HAL_GPIO_Init(GPIOB, &GPIO_InitStruct);

  /*Configure GPIO pins : IN1_Pin IN2_Pin IN3_Pin IN4_Pin
                           ROW1_Pin ROW2_Pin ROW3_Pin ROW4_Pin
                           ROW5_Pin ROW6_Pin ROW7_Pin ROW8_Pin */
  GPIO_InitStruct.Pin = IN1_Pin|IN2_Pin|IN3_Pin|IN4_Pin
                          |ROW1_Pin|ROW2_Pin|ROW3_Pin|ROW4_Pin
                          |ROW5_Pin|ROW6_Pin|ROW7_Pin|ROW8_Pin;
  GPIO_InitStruct.Mode = GPIO_MODE_OUTPUT_PP;
  GPIO_InitStruct.Pull = GPIO_NOPULL;
  GPIO_InitStruct.Speed = GPIO_SPEED_FREQ_LOW;
  HAL_GPIO_Init(GPIOD, &GPIO_InitStruct);

  /*Configure GPIO pin : USB_PowerSwitchOn_Pin */
  GPIO_InitStruct.Pin = USB_PowerSwitchOn_Pin;
  GPIO_InitStruct.Mode = GPIO_MODE_OUTPUT_PP;
  GPIO_InitStruct.Pull = GPIO_NOPULL;
  GPIO_InitStruct.Speed = GPIO_SPEED_FREQ_LOW;
  HAL_GPIO_Init(USB_PowerSwitchOn_GPIO_Port, &GPIO_InitStruct);

  /*Configure GPIO pin : USB_OverCurrent_Pin */
  GPIO_InitStruct.Pin = USB_OverCurrent_Pin;
  GPIO_InitStruct.Mode = GPIO_MODE_INPUT;
  GPIO_InitStruct.Pull = GPIO_NOPULL;
  HAL_GPIO_Init(USB_OverCurrent_GPIO_Port, &GPIO_InitStruct);

  /* EXTI interrupt init*/
  HAL_NVIC_SetPriority(EXTI0_IRQn, 5, 0);
  HAL_NVIC_EnableIRQ(EXTI0_IRQn);

  HAL_NVIC_SetPriority(EXTI2_IRQn, 5, 0);
  HAL_NVIC_EnableIRQ(EXTI2_IRQn);

  HAL_NVIC_SetPriority(EXTI3_IRQn, 5, 0);
  HAL_NVIC_EnableIRQ(EXTI3_IRQn);

  HAL_NVIC_SetPriority(EXTI4_IRQn, 5, 0);
  HAL_NVIC_EnableIRQ(EXTI4_IRQn);

}

void StartDefaultTask(void *argument)
{
  for(;;)
  {
    osDelay(1);
  }
}

void StartTask02(void *argument)
{
  /* USER CODE BEGIN StartTask02 */
  /* Infinite loop */
  for(;;)
  {
	  pc_command_processing();
	  bt_command_processing();
	  osDelay(1);
  }
  /* USER CODE END StartTask02 */
}

void StartTask03(void *argument)
{
  /* USER CODE BEGIN StartTask03 */
  /* Infinite loop */
  for(;;)
  {
	  get_rtc_time();
	  stepmotor_elva();
//	  button0_status_check();
//	  calculator();
	  osDelay(1);
  }
  /* USER CODE END StartTask03 */
}

void StartTask04(void *argument)
{
  /* USER CODE BEGIN StartTask04 */
  /* Infinite loop */
  for(;;)
  {
//	  ultrasonic_main();
	  dotmatrix_main();
	  if (TIM10_10ms_keypad_scan_timer >= 6)
		{
			TIM10_10ms_keypad_scan_timer=0;
			keypad_scanning();
		}
	  osDelay(1);
  }
  /* USER CODE END StartTask04 */
}

void HAL_TIM_PeriodElapsedCallback(TIM_HandleTypeDef *htim)
{
  if (htim->Instance == TIM1) {
    HAL_IncTick();
  }
  /* USER CODE BEGIN Callback 1 */
  if(htim->Instance == TIM10)
  		{
  			TIM10_10ms_counter++;  // 10ms timer counter
  			TIM10_10ms_keypad_scan_timer++;
  			t10ms_ultrasonic++;
#if 0
  			if (TIM10_10ms_keypad_scan_timer >= 6)
  			{
  				TIM10_10ms_keypad_scan_timer=0;
  				keypad_scanning();
  			}
#endif
  		}
  #if 0  // move to HAL_SYSTICK_CallBack

  	if(htim->Instance == TIM11)
  		{
  			TIM11_1ms_counter++;  // 1ms timer counter
  		}
  #endif
  /* USER CODE END Callback 1 */
}

void Error_Handler(void)
{
  __disable_irq();
  while (1)
  {
  }
}
